# AVR32EB14 register map
Vendor: Atmel; File version: 1.0
CPU: other r0p0, little endian, no MPU, no FPU, 4 interrupt priority bits
Registers are 8-bit, read-write, reset 0x0 unless marked. A register's access mark holds for its fields unless they carry their own. Offsets are from the block's base; lines under a group give offsets from that group; [hi:lo] are bit positions; {n}, {i} and the like mark numbered series; 'fields as' and 'values as' point back to an identical list; <NAME> marks a mode.

## Memory map
0x00800000 VPORTA size 0x4 — Virtual Ports
0x00800008 VPORTC size 0x4 — Virtual Ports
0x0080000C VPORTD size 0x4 — Virtual Ports
0x00800014 VPORTF size 0x4 — Virtual Ports
0x0080001C GPR size 0x4 — General Purpose Registers
0x00800034 CPU blocks up to offset 0xC
0x00800040 RSTCTRL size 0x2 — Reset controller
0x00800050 SLPCTRL size 0x1 — Sleep Controller
0x00800060 CLKCTRL blocks up to offset 0x1D — Clock controller
0x008000A0 BOD blocks up to offset 0xC — Bod interface
0x008000B2 VREF blocks up to offset 0x3 — Voltage reference
0x00800100 WDT size 0x2 — Watch-Dog Timer
0x00800110 CPUINT size 0x4 — Interrupt Controller
0x00800120 CRCSCAN size 0x3
0x00800140 RTC blocks up to offset 0x17 — Real-Time Counter
0x008001C0 CCL blocks up to offset 0x18 — Configurable Custom Logic
0x00800200 EVSYS blocks up to offset 0x39 — Event System
0x00800400 PORTA blocks up to offset 0x19 — I/O Ports
0x00800440 PORTC blocks up to offset 0x19 — I/O Ports
0x00800460 PORTD blocks up to offset 0x19 — I/O Ports
0x008004A0 PORTF blocks up to offset 0x19 — I/O Ports
0x008005E0 PORTMUX blocks up to offset 0xD — Port Multiplexer
0x00800600 ADC0 blocks up to offset 0x20 — Analog to Digital Converter
0x00800680 AC0 blocks up to offset 0x8 — Analog Comparator
0x00800688 AC1 blocks up to offset 0x8 — Analog Comparator
0x00800800 USART0 size 0xF — Universal Synchronous and Asynchronous Receiver and Transmitter
0x00800900 TWI0 size 0xF — Two-Wire Interface
0x00800940 SPI0 size 0x5 — Serial Peripheral Interface
0x00800A00 TCE0 blocks up to offset 0x40 — 16-bit Timer/Counter Type E
0x00800B00 TCB0 blocks up to offset 0xE — 16-bit Timer/Counter Type B
0x00800B10 TCB1 blocks up to offset 0xE — 16-bit Timer/Counter Type B
0x00800C00 TCF0 blocks up to offset 0x18 — 24-bit Timer/Counter for frequency generation
0x00800C80 WEX0 blocks up to offset 0x1E — Waveform Extension
0x00800F01 SYSCFG size 0x1 — System Configuration Registers
0x00801000 NVMCTRL blocks up to offset 0x10 — Non-volatile Memory Controller
0x00801040 LOCK size 0x4 — Lockbits
0x00801080 SIGROW blocks up to offset 0x20 — Signature row
0x00801100 BOOTROW size 0x1
0x00801200 USERROW size 0x1

## Interrupts
1 CRCSCAN_NMI (CPU)
2 BOD_VLM (CPU)
3 RTC_CNT (CPU)
4 RTC_PIT (CPU)
5 CCL_CCL (CPU)
6 PORTA_PORT (CPU)
7 WEX0_FAULTDET_FDFEVA_FDFEVB_FDFEVC (CPU)
8 TCE0_OVF (CPU)
9 TCE0_CMP0 (CPU)
10 TCE0_CMP1 (CPU)
11 TCE0_CMP2 (CPU)
12 TCE0_CMP3 (CPU)
13 TCB0_INT (CPU)
14 TCB1_INT (CPU)
15 TWI0_TWIS (CPU)
16 TWI0_TWIM (CPU)
17 SPI0_INT (CPU)
18 USART0_RXC (CPU)
19 USART0_DRE (CPU)
20 USART0_TXC (CPU)
21 PORTD_PORT (CPU)
22 TCF0_INT (CPU)
23 AC0_AC (CPU)
24 ADC0_ERROR (CPU)
25 ADC0_RESRDY (CPU)
26 ADC0_SAMPRDY (CPU)
27 AC1_AC (CPU)
28 PORTC_PORT (CPU)
29 PORTF_PORT (CPU)
30 NVMCTRL_EEREADY_FLREADY_NVMREADY (CPU)

## AC0 — Analog Comparator
Base 0x00800680
Same registers: AC1 0x00800688
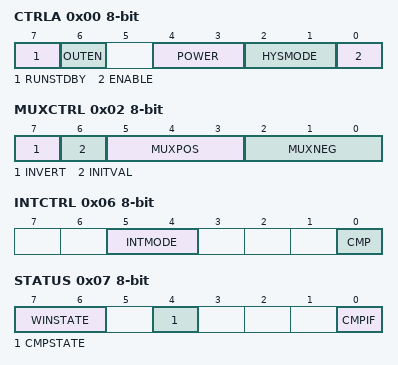
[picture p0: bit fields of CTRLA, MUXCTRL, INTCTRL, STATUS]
0x00 CTRLA — Control A
  [7] RUNSTDBY — Run in Standby Mode
  [6] OUTEN — Output Pad Enable
  [4:3] POWER — Power profile
    0=PROFILE0 (Power profile 0, Fastest response time, highest consumption); 1=PROFILE1 (Power profile 1)
  [2:1] HYSMODE — Hysteresis Mode
    0=NONE (No hysteresis); 1=SMALL (Small hysteresis); 2=MEDIUM (Medium hysteresis); 3=LARGE (Large hysteresis)
  [0] ENABLE
0x01 CTRLB — Control B
  [1:0] WINSEL — Window selection mode
    0=DISABLED (Window function disabled); 1=UPSEL1 (Select ACn+1 as upper limit in window compare)
0x02 MUXCTRL — Mux Control A
  [7] INVERT — Invert AC Output
  [6] INITVAL — AC Output Initial Value
    0=LOW (Output initialized to 0); 1=HIGH (Output initialized to 1)
  [5:3] MUXPOS — Positive Input MUX Selection
    {v}=AINP{v} (Positive Pin {v}) (v=0..6)
  [2:0] MUXNEG — Negative Input MUX Selection
    {v}=AINN{v} (Negative Pin {v}) (v=0..3); 4=DACREF (DAC Reference)
0x05 DACREF — DAC Voltage Reference
0x06 INTCTRL — Interrupt Control
  [5:4] INTMODE — Interrupt Mode
    0=ABOVE (Window interrupt when input above both references); 1=INSIDE (Window interrupt when input betweeen references); 2=BELOW (Window interrupt when input below both references); 3=OUTSIDE (Window interrupt when input outside reference)
  [0] CMP — Interrupt Enable
0x07 STATUS
  [7:6] WINSTATE ro — Analog Comparator Window State
    0=ABOVE (Above window); 1=INSIDE (Inside window); 2=BELOW (Below window)
  [4] CMPSTATE ro — Analog Comparator State
  [0] CMPIF — Analog Comparator Interrupt Flag
